# I94100_v1_3 register map
File version: 1.0
Registers are 32-bit, read-write, reset 0x0 unless marked. A register's access mark holds for its fields unless they carry their own. Offsets are from the block's base; [hi:lo] are bit positions; {n}, {i} and the like mark numbered series.

## DPWM — DPWM Register Map
Base 0x40064000
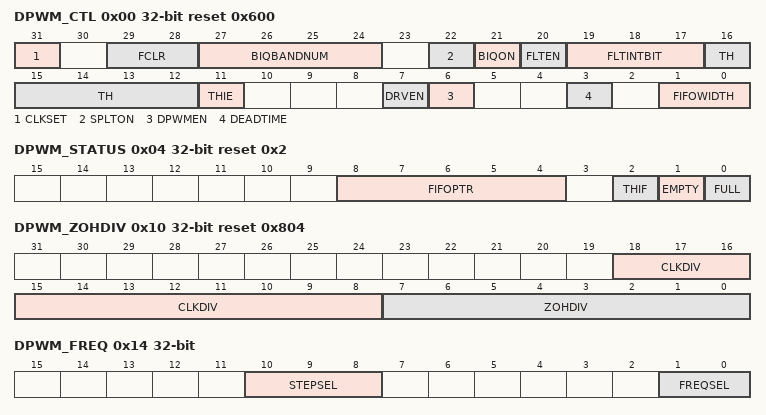
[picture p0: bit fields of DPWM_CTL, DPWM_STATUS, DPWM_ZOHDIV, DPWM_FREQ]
0x00 DPWM_CTL reset 0x600 — DPWM Control Register
  [31] CLKSET — Working Clock Selection
    0=512 fs working clock; 1=500 fs working clock
  [29:28] FCLR — FIFO Clear. Note 1: To clear the FIFO, need to write FCLR (DPWM_CTL[29:28]) to 11b, and can read the EMPTY (DPWM_STATUS[1]) bit to make sure that the FIFO has been cleared. Note 2: This field is auto cleared by hardware.
    3=Clear the FIFO
  [27:24] BIQBANDNUM — BIQ Band Number Setting (Total 10 Bands). This field represents the required number of bands. The minimum number is 1 and can up to 10 when user enables biquad filter or splitter.
  [22] SPLTON — Splitter Enable Bit. Note: Splitter shared biquad filter 4 bands, the minimum number of BIQBANDNUM is 4, if splitter is enabled.
    0=4-band splitter Disabled; 1=4-band splitter Enabled
  [21] BIQON — BIQ Enable Bit
    0=Biquad filter Disabled; 1=Biquad filter Enabled
  [20] FLTEN — Floating Point Format Enable Bit
    0=Input data is fixed point; 1=Input data is single precision point
  [19:17] FLTINTBIT — Floating Integer Bits Setting
    0=Integer is 0, Data range +/- 0.999; 1=Integer is 1, Data range +/- 1.9999; 2=Integer is 2, Data range +/- 3.9999
  [16:12] TH — FIFO Threshold Level. If the valid data count of the FIFO data buffer is less than or equal to TH (DPWM_CTL[16:12]) setting, the THIF (DPWM_STATUS[2]) will set to 1, else the THIF (DPWM_STATUS[2]) will be cleared to 0.
  [11] THIE — FIFO Threshold Interrupt
    0=FIFO threshold interrupt Disabled; 1=FIFO threshold interrupt Enabled
  [7] DRVEN — Driver Enable Bit
    0=Audio DPWM driver Disabled; 1=Audio DPWM driver Enabled
  [6] DPWMEN — Audio DPWM Modulator Enable
    0=Audio DPWM modulator Disabled; 1=Audio DPWM modulator Enabled
  [3] DEADTIME — Driver Dead Time Control. Enabling this bit will insert an additional clock cycle deadtime into the switching of PMOS and NMOS driver transistors.
  [1:0] FIFOWIDTH — FIFO Data Width. This bit field is used to define the bit-width of data word and valid bits in register DPWM_FIFO. Note: When FLTEN is "0", FIFOWIDTH is for fixed point setting.
    0=The bit-width of data word is 24-bit, valid bits is DPWM_FIFO[31:8]; 1=The bit-width of data word is 16-bit, valid bits is DPWM_FIFO[15:0]; 2=The bit-width of data word is 8-bit, valid bits is DPWM_FIFO[7:0]; 3=The bit-width of data word is 24-bit, valid bits is DPWM_FIFO[23:0]
0x04 DPWM_STATUS ro reset 0x2
  [8:4] FIFOPTR — FIFO Pointer (Read Only). The FULL (DPWM_STATUS[0]) and FIFOPTR (DPWM_STATUS[8:4]) indicates the field that the valid data count within the DPWM FIFO buffer. The maximum value shown in FIFOPTR is 31. When the using level of DPWM FIFO buffer equal to 32, The FULL (DPWM_STATUS[0]) is set to 1.
  [2] THIF — FIFO Threshold Interrupt Status (Read Only)
    0=The valid data count within the FIFO data buffer is more than the setting value of TH (DPWM_CTL[16:12]); 1=The valid data count within the FIFO data buffer is less than or equal to the setting value of TH (DPWM_CTL[16:12])
  [1] EMPTY — FIFO Empty (Read Only)
    0=FIFO is not empty; 1=FIFO is empty
  [0] FULL — FIFO Full (Read Only)
    0=FIFO is not full; 1=FIFO is full
0x08 DPWM_PDMACTL — DPWM PDMA Control Register
  [0] PDMAEN — PDMA Transfer Enable Bit
    0=PDMA data transfer Disabled; 1=PDMA data transfer Enabled
0x0C DPWM_FIFO wo — DPWM FIFO Data Input Register
  [31:0] FIFO — FIFO Data Input Register. DPWM contains 32 words (32x32 bit) data buffer for data transmit. A write to this register pushes data onto the FIFO data buffer and increments the write pointer. This is the address that PDMA writes audio data to. The remaining word number is indicated by FIFOPTR (DPWM_STATUS[8:4]).
0x10 DPWM_ZOHDIV reset 0x804 — DPWM Zero Order Hold Division Register
  [18:8] CLKDIV — Clock Divider. Divider to generate the DPWM_CLK where F_ DPWM _CLK_SRC is the frequency of DPWM module clock source, which is defined in the clock control register DPWMSEL (CLK_CLKSEL2[13:12]) and F_DPWM_CLK is the frequency of DPWM module working clock (DPWM_CLK). Note 1: If fs is 48 kHz, the frequency of DPWM_CLK must be 24.576 MHz or 24 MHz according to the value of CLKSET (DPWM_CTL[31]). Note 2: If fs is 96 kHz, the frequency of DPWM_CLK must be 49.152 MHz or 48 MHz according to the value of CLKSET (DPWM_CTL[31]).
  [7:0] ZOHDIV — Zero Order Hold, Down-sampling Divisor. The input sample rate of the DPWM is set by DPWM_CLK frequency and the divisor set in this register by the following formula:
0x14 DPWM_FREQ — DPWM Output Signal Frequency Control Register
  [10:8] STEPSEL — Output Signal Frequency
    0=Output signal frequency is 614 kHz; 1=Output signal frequency is 512 kHz; 2=Output signal frequency is 438 kHz; 3=Output signal frequency is 384 kHz; 4=Output signal frequency is 341 kHz; 5=Output signal frequency is 307 kHz
  [1:0] FREQSEL — Output Signal FrequencySelection
    0=Output signal frequency is 384 kHz; 1=Output signal frequency is 307 kHz. Output signal frequency depends on STEPSEL (DPWM_FREQ[10:8])
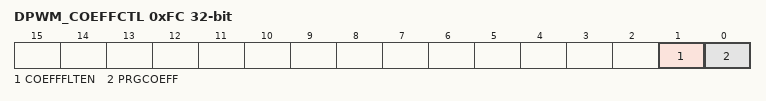
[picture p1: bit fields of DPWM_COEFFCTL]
0xFC DPWM_COEFFCTL — BIQ Coefficient Control
  [1] COEFFFLTEN — Coefficient Single Floating Point
    0=Coefficient is fixed point; 1=Coefficient is single floating point
  [0] PRGCOEFF — Coefficient Programming Control. Note: This bit must be truned off when BIQON (DPWM_CTL[21]) in on.
    0=Coefficient RAM is in normal mode; 1=Coefficient RAM is under programming mode
{0x100+4i} DPWM_COEFF{i} (i=0..2) — Coefficient B{i} Transfer Function for Band 1. Fixed Point - 3.21 Format. Floating Point - Single Precision Point
  [23:0] COEFFDAT — Coefficient Data.
0x10C DPWM_COEFF3 — Coefficient A1 Transfer Function for Band 1. Fixed Point - 3.21 Format. Floating Point - Single Precision Point
  [23:0] COEFFDAT — Coefficient Data.
0x110 DPWM_COEFF4 — Coefficient A2 Transfer Function for Band 1. Fixed Point - 3.21 Format. Floating Point - Single Precision Point
  [23:0] COEFFDAT — Coefficient Data.
{0x100+4i} DPWM_COEFF{i} (i=5..7) — Coefficient B{i-5} Transfer Function for Band 2. Fixed Point - 3.21 Format. Floating Point - Single Precision Point
  [23:0] COEFFDAT — Coefficient Data.
0x120 DPWM_COEFF8 — Coefficient A1 Transfer Function for Band 2. Fixed Point - 3.21 Format. Floating Point - Single Precision Point
  [23:0] COEFFDAT — Coefficient Data.
0x124 DPWM_COEFF9 — Coefficient A2 Transfer Function for Band 2. Fixed Point - 3.21 Format. Floating Point - Single Precision Point
  [23:0] COEFFDAT — Coefficient Data.
{0x100+4i} DPWM_COEFF{i} (i=10..12) — Coefficient B{i-10} Transfer Function for Band 3. Fixed Point - 3.21 Format. Floating Point - Single Precision Point
  [23:0] COEFFDAT — Coefficient Data.
0x134 DPWM_COEFF13 — Coefficient A1 Transfer Function for Band 3. Fixed Point - 3.21 Format. Floating Point - Single Precision Point
  [23:0] COEFFDAT — Coefficient Data.
0x138 DPWM_COEFF14 — Coefficient A2 Transfer Function for Band 3. Fixed Point - 3.21 Format. Floating Point - Single Precision Point
  [23:0] COEFFDAT — Coefficient Data.
{0x100+4i} DPWM_COEFF{i} (i=15..17) — Coefficient B{i-15} Transfer Function for Band 4. Fixed Point - 3.21 Format. Floating Point - Single Precision Point
  [23:0] COEFFDAT — Coefficient Data.
0x148 DPWM_COEFF18 — Coefficient A1 Transfer Function for Band 4. Fixed Point - 3.21 Format. Floating Point - Single Precision Point
  [23:0] COEFFDAT — Coefficient Data.
0x14C DPWM_COEFF19 — Coefficient A2 Transfer Function for Band 4. Fixed Point - 3.21 Format. Floating Point - Single Precision Point
  [23:0] COEFFDAT — Coefficient Data.
{0x100+4i} DPWM_COEFF{i} (i=20..22) — Coefficient B{i-20} Transfer Function for Band 5. Fixed Point - 3.21 Format. Floating Point - Single Precision Point
  [23:0] COEFFDAT — Coefficient Data.
0x15C DPWM_COEFF23 — Coefficient A1 Transfer Function for Band 5. Fixed Point - 3.21 Format. Floating Point - Single Precision Point
  [23:0] COEFFDAT — Coefficient Data.
0x160 DPWM_COEFF24 — Coefficient A2 Transfer Function for Band 5. Fixed Point - 3.21 Format. Floating Point - Single Precision Point
  [23:0] COEFFDAT — Coefficient Data.
{0x100+4i} DPWM_COEFF{i} (i=25..27) — Coefficient B{i-25} Transfer Function for Band 6. Fixed Point - 3.21 Format. Floating Point - Single Precision Point
  [23:0] COEFFDAT — Coefficient Data.
0x170 DPWM_COEFF28 — Coefficient A1 Transfer Function for Band 6. Fixed Point - 3.21 Format. Floating Point - Single Precision Point
  [23:0] COEFFDAT — Coefficient Data.
0x174 DPWM_COEFF29 — Coefficient A2 Transfer Function for Band 6. Fixed Point - 3.21 Format. Floating Point - Single Precision Point
  [23:0] COEFFDAT — Coefficient Data.
{0x100+4i} DPWM_COEFF{i} (i=30..32) — Coefficient B{i-30} Transfer Function for Band 7. Fixed Point - 3.21 Format. Floating Point - Single Precision Point
  [23:0] COEFFDAT — Coefficient Data.
0x184 DPWM_COEFF33 — Coefficient A1 Transfer Function for Band 7. Fixed Point - 3.21 Format. Floating Point - Single Precision Point
  [23:0] COEFFDAT — Coefficient Data.
0x188 DPWM_COEFF34 — Coefficient A2 Transfer Function for Band 7. Fixed Point - 3.21 Format. Floating Point - Single Precision Point
  [23:0] COEFFDAT — Coefficient Data.
{0x100+4i} DPWM_COEFF{i} (i=35..37) — Coefficient B{i-35} Transfer Function for Band 8. Fixed Point - 3.21 Format. Floating Point - Single Precision Point
  [23:0] COEFFDAT — Coefficient Data.
0x198 DPWM_COEFF38 — Coefficient A1 Transfer Function for Band 8. Fixed Point - 3.21 Format. Floating Point - Single Precision Point
  [23:0] COEFFDAT — Coefficient Data.
0x19C DPWM_COEFF39 — Coefficient A2 Transfer Function for Band 8. Fixed Point - 3.21 Format. Floating Point - Single Precision Point
  [23:0] COEFFDAT — Coefficient Data.
{0x100+4i} DPWM_COEFF{i} (i=40..42) — Coefficient B{i-40} Transfer Function for Band 9. Fixed Point - 3.21 Format. Floating Point - Single Precision Point
  [23:0] COEFFDAT — Coefficient Data.
0x1AC DPWM_COEFF43 — Coefficient A1 Transfer Function for Band 9. Fixed Point - 3.21 Format. Floating Point - Single Precision Point
  [23:0] COEFFDAT — Coefficient Data.
0x1B0 DPWM_COEFF44 — Coefficient A2 Transfer Function for Band 9. Fixed Point - 3.21 Format. Floating Point - Single Precision Point
  [23:0] COEFFDAT — Coefficient Data.
{0x100+4i} DPWM_COEFF{i} (i=45..47) — Coefficient B{i-45} Transfer Function for Band 10. Fixed Point - 3.21 Format. Floating Point - Single Precision Point
  [23:0] COEFFDAT — Coefficient Data.
0x1C0 DPWM_COEFF48 — Coefficient A1 Transfer Function for Band 10. Fixed Point - 3.21 Format. Floating Point - Single Precision Point
  [23:0] COEFFDAT — Coefficient Data.
0x1C4 DPWM_COEFF49 — Coefficient A2 Transfer Function for Band 10. Fixed Point - 3.21 Format. Floating Point - Single Precision Point
  [23:0] COEFFDAT — Coefficient Data.
